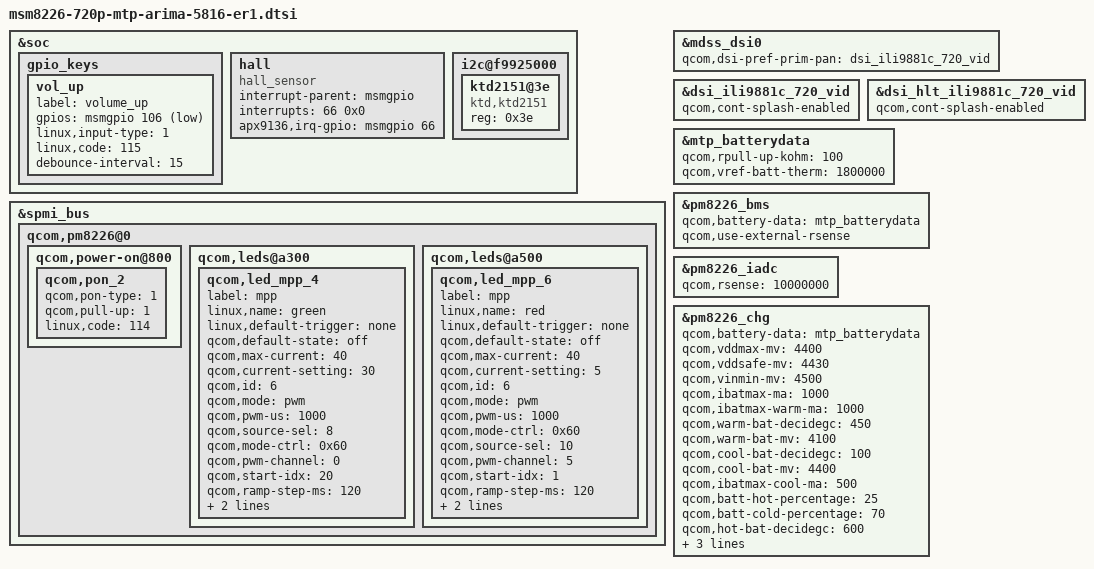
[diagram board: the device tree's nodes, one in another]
/include/ "msm8226-720p-mtp-arima-5816-sr.dtsi"

// [5816][Keypad][akenhsu] Porting Vol keys for ER1(ASUS) 20150831 BEGIN
&soc {
	gpio_keys {
		vol_up {
			label = "volume_up";
			gpios = <&msmgpio 106 0x1>;
			linux,input-type = <1>;
			linux,code = <115>;
			// gpio-key,wakeup;
			debounce-interval = <15>;
		};

	};
// [5816][sensor][potingchang] write gpio in dtsi 20150922 BEGIN
// [5816][sensor][potingchang] Add Hall-sensor driver in Linux 20150828 BEGIN
	hall {
		compatible = "hall_sensor";
		interrupt-parent = <&msmgpio>;
		interrupts = <66 0x0>;
		apx9136,irq-gpio = <&msmgpio 66 0x00>;
	};
// [5816][sensor][potingchang] 20150828 END
// [5816][sensor][potingchang] 20150922 END

//[Arima_5816][LCM][RaymondLin]Add LCM gate drive Kinetic KTD2151 begin
i2c@f9925000 {
		ktd2151@3e {
		compatible = "ktd,ktd2151";
		reg = <0x3e>;
	        };
	};

//[Arima_5816][LCM][RaymondLin]Add LCM gate drive Kinetic KTD2151 end

};

&spmi_bus {
	qcom,pm8226@0 {
		qcom,power-on@800 {
			qcom,pon_2 {
				qcom,pon-type = <1>;
				qcom,pull-up = <1>;
				linux,code = <114>;
			};
		};
	};
};
// [5816][Keypad][akenhsu] 20150831 END

// [5816][LED][akenhsu] Porting RGB LEDs for ER1(ASUS) 20150831 BEGIN
&spmi_bus {
	qcom,pm8226@0 {
		qcom,leds@a300 {
			status = "okay";
			qcom,led_mpp_4 {
				label = "mpp";
				linux,name = "green";
				linux,default-trigger = "none";
				qcom,default-state = "off";
				qcom,max-current = <40>;
				qcom,current-setting = <30>;
				qcom,id = <6>;
				qcom,mode = "pwm";
				qcom,pwm-us = <1000>;
				qcom,source-sel = <8>;
				qcom,mode-ctrl = <0x60>;
				qcom,pwm-channel = <0>;
				qcom,start-idx = <20>;
				qcom,ramp-step-ms = <120>;
				qcom,duty-pcts = [00 00 50 99 99 99 50 00];
				qcom,use-blink;
			};
		};

		qcom,leds@a500 {
			status = "okay";
			qcom,led_mpp_6 {
				label = "mpp";
				linux,name = "red";
				linux,default-trigger = "none";
				qcom,default-state = "off";
				qcom,max-current = <40>;
				qcom,current-setting = <5>;
				qcom,id = <6>;
				qcom,mode = "pwm";
				qcom,pwm-us = <1000>;
				qcom,mode-ctrl = <0x60>;
				qcom,source-sel = <10>;
				qcom,pwm-channel = <5>;
				qcom,start-idx = <1>;
				qcom,ramp-step-ms = <120>;
				qcom,duty-pcts = [00 00 50 99 99 99 50 00];
				qcom,use-blink;
			};
		};
	};
};
// [5816][LED][akenhsu] 20150831 END

/*[Arima_5816][LCM][RaymondLin] LCM Truly ili9881C driver porting 20150921 begin */
&mdss_dsi0 {
/*	qcom,dsi-pref-prim-pan = <&dsi_nt35590_720_vid>; */
    qcom,dsi-pref-prim-pan = <&dsi_ili9881c_720_vid>;
};
/*[Arima_5816][LCM][RaymondLin] LCM Truly ili9881C enable cont-splash 20151005 begin */
&dsi_ili9881c_720_vid {
	qcom,cont-splash-enabled;
};
/*[Arima_5816][LCM][RaymondLin] LCM Truly ili9881C enable cont-splash 20151005 end */
/*[Arima_5816][LCM][RaymondLin] LCM Truly ili9881C driver porting 20150921 end */

/*[Arima_5816][LCM][RaymondLin] LCM 2nd source HLT ili9881C driver porting 20151104 begin */
&dsi_hlt_ili9881c_720_vid {
	qcom,cont-splash-enabled;
};
/*[Arima_5816][LCM][RaymondLin] LCM 2nd source HLT ili9881C driver porting 20151104 end */
/*[Arima_5816][bozhi_lin] apply er1 battery data 20150924 begin*/
&mtp_batterydata{
	qcom,rpull-up-kohm = <100>;
	qcom,vref-batt-therm = <1800000>;
	/include/ "batterydata-arima-4v38-2910mah-ZC551KL.dtsi"
};

&pm8226_bms {
	qcom,battery-data = <&mtp_batterydata>;
/*[Arima_5816][bozhi_lin] follow hardware design set battery rsense to external 20160114 begin*/
	qcom,use-external-rsense;
/*[Arima_5816][bozhi_lin] 20160114 end*/
};

/*[Arima_5816][bozhi_lin] follow hardware design set battery rsense to external 20160114 begin*/
&pm8226_iadc {
	qcom,rsense = <10000000>;
};
/*[Arima_5816][bozhi_lin] 20160114 end*/

&pm8226_chg {
	qcom,battery-data = <&mtp_batterydata>;
/*[Arima_5816][bozhi_lin] fine tune charging parameters, set vmax to 4.4V and terminate current to 50mA 20151022 begin*/
	qcom,vddmax-mv = <4400>;
	qcom,vddsafe-mv = <4430>;
	qcom,vinmin-mv = <4500>;
/*[Arima_5816][bozhi_lin] 20151022 end*/
/*[Arima_5816][bozhi_lin] set battery temperature JEITA parameters from hw 20151126 begin*/
/*[Arima_5816][bozhi_lin] set battery temperature JEITA parameters to meet spec 20151111 begin*/
/*[Arima_5816][bozhi_lin] set battery temperature JEITA parameters to meet spec 20151106 begin*/
/*[Arima_5816][bozhi_lin] set battery temperature JEITA parameters to meet spec 20151022 begin*/
	qcom,ibatmax-ma = <1000>;
	qcom,ibatmax-warm-ma = <1000>;
	qcom,warm-bat-decidegc = <450>;
	qcom,warm-bat-mv = <4100>;
	qcom,cool-bat-decidegc = <100>;
	qcom,cool-bat-mv = <4400>;
	qcom,ibatmax-cool-ma = <500>;
	qcom,batt-hot-percentage = <25>;
	qcom,batt-cold-percentage = <70>;
/*[Arima_5816][bozhi_lin] 20151022 end*/
/*[Arima_5816][bozhi_lin] add temp_cold and temp_hot for disable charging to meet spec 20151023 begin*/
	qcom,hot-bat-decidegc = <600>;
	qcom,cold-bat-decidegc = <0>;
/*[Arima_5816][bozhi_lin] 20151023 end*/
/*[Arima_5816][bozhi_lin] 20151106 end*/
/*[Arima_5816][bozhi_lin] 20151111 end*/
/*[Arima_5816][bozhi_lin] 20151126 end*/
/*[Arima_5816][bozhi_lin] enable charging timer and set set recharge voltage 20151130 begin*/
	qcom,vbatdet-delta-mv = <100>;
/*[Arima_5816][bozhi_lin] disable charging timer 20151123 begin*/
	qcom,tchg-mins = <512>;
/*[Arima_5816][bozhi_lin] 20151123 end*/
/*[Arima_5816][bozhi_lin] 20151130 end*/
};
/*[Arima_5816][bozhi_lin] 20150924 end*/
